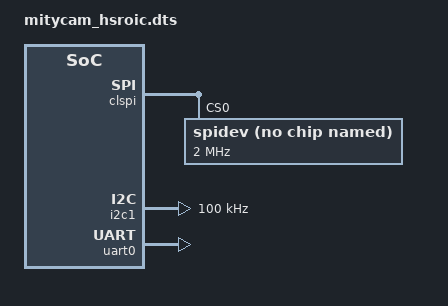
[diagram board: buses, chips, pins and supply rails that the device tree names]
/*
 * Copyright (C) 2014-2015 Altera Corporation <www.altera.com>
 *
 * This program is free software; you can redistribute it and/or modify
 * it under the terms of the GNU General Public License as published by
 * the Free Software Foundation; either version 2 of the License, or
 * (at your option) any later version.
 *
 * This program is distributed in the hope that it will be useful,
 * but WITHOUT ANY WARRANTY; without even the implied warranty of
 * MERCHANTABILITY or FITNESS FOR A PARTICULAR PURPOSE.  See the
 * GNU General Public License for more details.
 *
 * You should have received a copy of the GNU General Public License
 * along with this program.  If not, see <http://www.gnu.org/licenses/>.
 */

/dts-v1/;
#include "mitysom_a10s_dsc.dtsi"

/ {
	aliases {
		spi0 = &spi0;
		serial1 = &uart0;
	};

	soc {
		hps_lw_bus: bus@0ff200000 {
			compatible = "simple-bus";
			reg = <0xFF200000 0x00200000>;
			#address-cells = <1>;
			#size-cells = <1>;
			ranges = <0x0 0xFF200000 0x00200000>;
			status = "okay";

			sysid_qsys: sysid@0000 {
				compatible = "altr,sysid-1.0";
				reg = <0x000000 0x08>;
			};

			clspi: spi@1000 {
				compatible = "cl,spi-1.0";
				#address-cells = <1>;
				#size-cells = <0>;
				reg = <0x00001000 0x0100>;
				interrupts = <0 21 4>;
				master-ref-clk = <42000000>;
				num-chipselect = <8>;
				bus-num = <3>;

				spidev@1 {
					compatible = "cl,spidev";
					spi-max-frequency = <2000000>;
					reg = <0>;
				};
			};
		};

		streamer0: streamer@80000000 {
			compatible = "uio,irq";
			interrupts = <0 19 4>;
		};
	};
};

&i2c1 {
	status = "okay";
	clock-frequency = <100000>;
        i2c-sda-hold-time-ns = <500>;


	/* USB IO Tri-Color LED */
	/* disabled - used directly by ARM software */
	/* 
	led@62 {
		compatible = "nxp,pca9553";
		reg = <0x62>;
	}; */

	/* Sensor board */

};

/* FX3 comms interface */
&uart0 {
	status = "okay";
};

